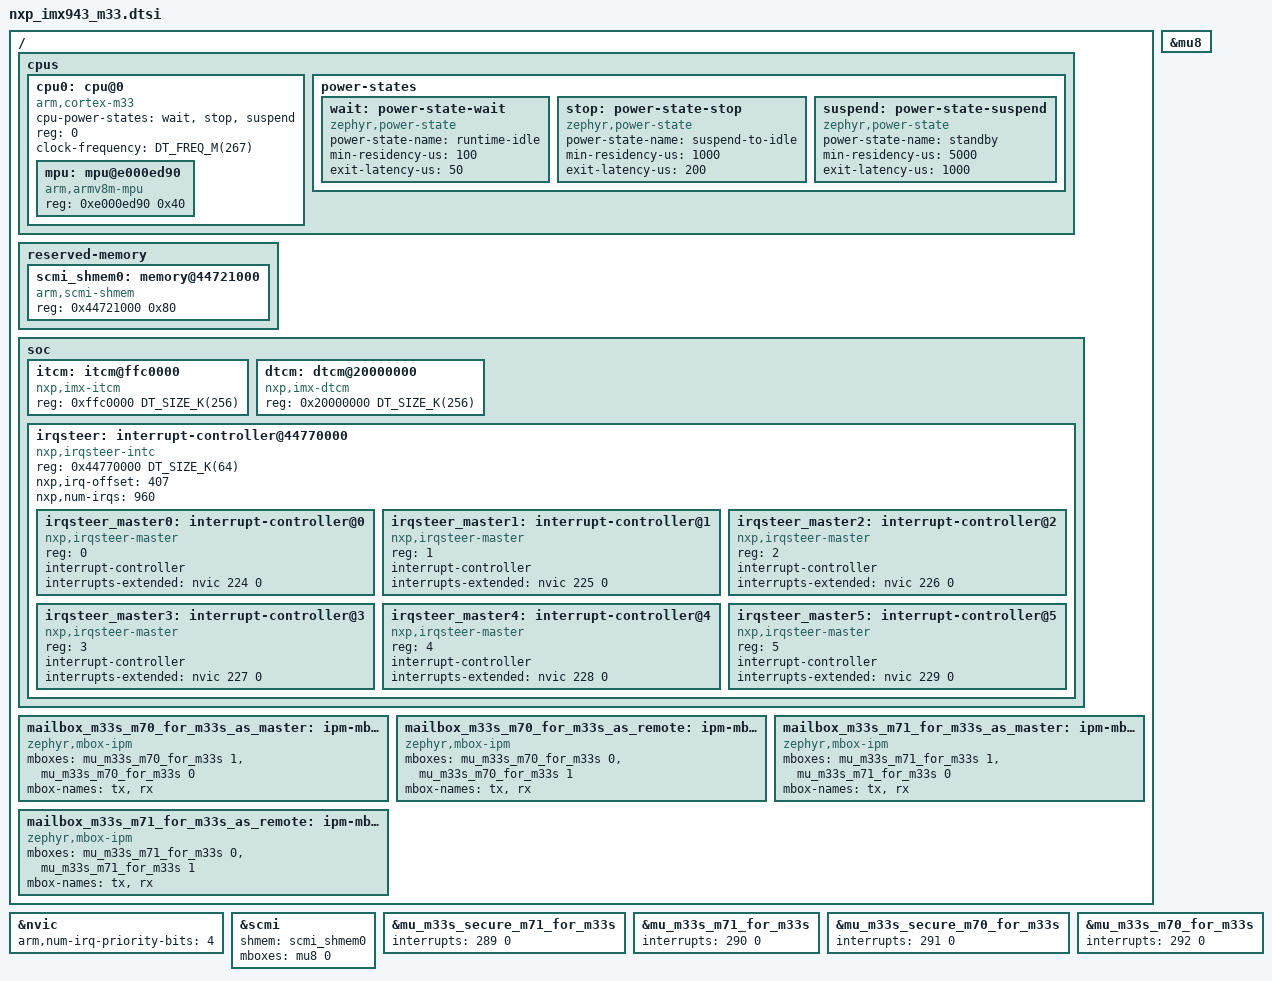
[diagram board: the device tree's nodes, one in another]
/*
 * Copyright 2025 NXP
 *
 * SPDX-License-Identifier: Apache-2.0
 */

#include <arm/armv8-m.dtsi>
#include <mem.h>
#include <nxp/imx/nxp_imx94x.dtsi>
#include <freq.h>

/ {
	cpus {
		#address-cells = <1>;
		#size-cells = <0>;

		cpu0: cpu@0 {
			device_type = "cpu";
			compatible = "arm,cortex-m33";
			cpu-power-states = <&wait &stop &suspend>;
			reg = <0>;
			clock-frequency = <DT_FREQ_M(267)>;

			#address-cells = <1>;
			#size-cells = <1>;

			mpu: mpu@e000ed90 {
				compatible = "arm,armv8m-mpu";
				reg = <0xe000ed90 0x40>;
			};
		};

		power-states {
			wait: power-state-wait {
				compatible = "zephyr,power-state";
				power-state-name = "runtime-idle";
				min-residency-us = <100>;
				exit-latency-us = <50>;
			};

			stop: power-state-stop {
				compatible = "zephyr,power-state";
				power-state-name = "suspend-to-idle";
				min-residency-us = <1000>;
				exit-latency-us = <200>;
			};

			suspend: power-state-suspend {
				compatible = "zephyr,power-state";
				power-state-name = "standby";
				min-residency-us = <5000>;
				exit-latency-us = <1000>;
			};
		};
	};

	reserved-memory {
		#address-cells = <1>;
		#size-cells = <1>;

		scmi_shmem0: memory@44721000 {
			compatible = "arm,scmi-shmem";
			reg = <0x44721000 0x80>;
		};
	};

	soc {
		itcm: itcm@ffc0000 {
			compatible = "nxp,imx-itcm";
			reg = <0xffc0000 DT_SIZE_K(256)>;
		};

		dtcm: dtcm@20000000 {
			compatible = "nxp,imx-dtcm";
			reg = <0x20000000 DT_SIZE_K(256)>;
		};

		irqsteer: interrupt-controller@44770000 {
			compatible = "nxp,irqsteer-intc";
			#size-cells = <0>;
			#address-cells = <1>;
			reg = <0x44770000 DT_SIZE_K(64)>;
			nxp,irq-offset = <407>;
			nxp,num-irqs = <960>;

			irqsteer_master0: interrupt-controller@0 {
				compatible = "nxp,irqsteer-master";
				reg = <0>;
				interrupt-controller;
				#interrupt-cells = <2>;
				interrupts-extended = <&nvic 224 0>;
			};

			irqsteer_master1: interrupt-controller@1 {
				compatible = "nxp,irqsteer-master";
				reg = <1>;
				interrupt-controller;
				#interrupt-cells = <2>;
				interrupts-extended = <&nvic 225 0>;
			};

			irqsteer_master2: interrupt-controller@2 {
				compatible = "nxp,irqsteer-master";
				reg = <2>;
				interrupt-controller;
				#interrupt-cells = <2>;
				interrupts-extended = <&nvic 226 0>;
			};

			irqsteer_master3: interrupt-controller@3 {
				compatible = "nxp,irqsteer-master";
				reg = <3>;
				interrupt-controller;
				#interrupt-cells = <2>;
				interrupts-extended = <&nvic 227 0>;
			};

			irqsteer_master4: interrupt-controller@4 {
				compatible = "nxp,irqsteer-master";
				reg = <4>;
				interrupt-controller;
				#interrupt-cells = <2>;
				interrupts-extended = <&nvic 228 0>;
			};

			irqsteer_master5: interrupt-controller@5 {
				compatible = "nxp,irqsteer-master";
				reg = <5>;
				interrupt-controller;
				#interrupt-cells = <2>;
				interrupts-extended = <&nvic 229 0>;
			};
		};
	};

	mailbox_m33s_m70_for_m33s_as_master: ipm-mbox0 {
		compatible = "zephyr,mbox-ipm";
		mboxes = <&mu_m33s_m70_for_m33s 1>, <&mu_m33s_m70_for_m33s 0>;
		mbox-names = "tx", "rx";
	};

	mailbox_m33s_m70_for_m33s_as_remote: ipm-mbox1 {
		compatible = "zephyr,mbox-ipm";
		mboxes = <&mu_m33s_m70_for_m33s 0>, <&mu_m33s_m70_for_m33s 1>;
		mbox-names = "tx", "rx";
	};

	mailbox_m33s_m71_for_m33s_as_master: ipm-mbox2 {
		compatible = "zephyr,mbox-ipm";
		mboxes = <&mu_m33s_m71_for_m33s 1>, <&mu_m33s_m71_for_m33s 0>;
		mbox-names = "tx", "rx";
	};

	mailbox_m33s_m71_for_m33s_as_remote: ipm-mbox3 {
		compatible = "zephyr,mbox-ipm";
		mboxes = <&mu_m33s_m71_for_m33s 0>, <&mu_m33s_m71_for_m33s 1>;
		mbox-names = "tx", "rx";
	};
};

&nvic {
	arm,num-irq-priority-bits = <4>;
};

&scmi {
	shmem = <&scmi_shmem0>;
	mboxes = <&mu8 0>;
};

&mu8 {
	status = "okay";
};

&mu_m33s_secure_m71_for_m33s {
	interrupts = <289 0>;
	status = "okay";
};

&mu_m33s_m71_for_m33s {
	interrupts = <290 0>;
	status = "okay";
};

&mu_m33s_secure_m70_for_m33s {
	interrupts = <291 0>;
	status = "okay";
};

&mu_m33s_m70_for_m33s {
	interrupts = <292 0>;
	status = "okay";
};
